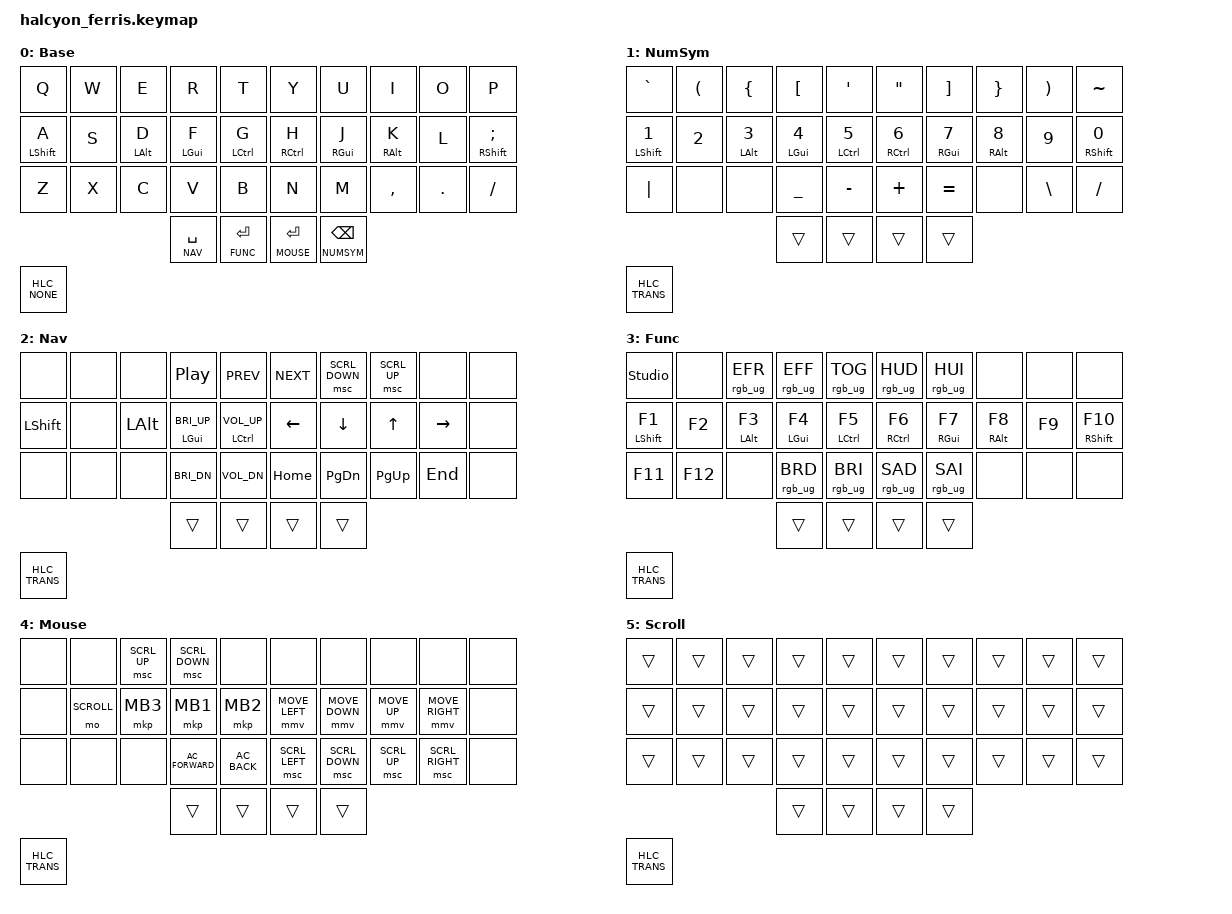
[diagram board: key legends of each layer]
/*
 * Halcyon Ferris keymap — 1:1 port of my ZSA Voyager Oryx layout
 * "Nima's 34 keys" (layout eVJKy, revision pjMjbv).
 *
 * Only the 34 Voyager keys that were actually bound are used, so the
 * layout maps directly onto the Ferris. Layer numbers match Oryx.
 *
 * Hardware: Halcyon wireless controllers, coin cell battery boards,
 * e-paper display module on the left half, Cirque touchpad on the right half.
 * The touchpad works on every layer as a mouse automatically.
 * The wired copy (flake output `firmware-wired`, RP2040 controllers, same
 * modules, no dongle) builds from this same file: ZMK picks it by shield
 * name, so the two keyboards cannot drift apart.
 * (&studio_unlock works on whichever part is the central: the dongle on
 * the wireless build, the left half on the wired one.)
 *
 * Position reference (34 keys + 10 Halcyon module slots at the end):
 *
 *   0  1  2  3  4     5  6  7  8  9
 *  10 11 12 13 14    15 16 17 18 19
 *  20 21 22 23 24    25 26 27 28 29
 *           30 31    32 33
 */

// Wheel scrolling with the &msc keys (Nav and Mouse layers): units per
// tick at full speed, ZMK's default is 10. Raise/lower to taste.
#define ZMK_POINTING_DEFAULT_SCRL_VAL 400

#include <behaviors.dtsi>
#include <dt-bindings/zmk/bt.h>
#include <dt-bindings/zmk/keys.h>
#include <dt-bindings/zmk/pointing.h>
#include <dt-bindings/zmk/rgb.h>

#define BASE   0
#define NUMSYM 1
#define NAV    2
#define FUNC   3
#define MOUSE  4
#define SCROLL 5   // held via S on the Mouse layer: the touchpad scrolls

// Halcyon module key slots (unused by the e-paper / Cirque modules)
#define HLC_NONE  &none  &none  &none  &none  &none   &none  &none  &none  &none  &none
#define HLC_TRANS &trans &trans &trans &trans &trans  &trans &trans &trans &trans &trans

// Key position groups for positional hold-taps (module slots 34-43 excluded).
#define KEYS_L 0 1 2 3 4  10 11 12 13 14  20 21 22 23 24
#define KEYS_R 5 6 7 8 9  15 16 17 18 19  25 26 27 28 29
#define THUMBS 30 31 32 33

// Layer-taps (thumbs): "balanced" = the layer wins as soon as a key on it is
// pressed *and released* while the thumb is down, so "hold Space, tap J"
// gives Down immediately instead of " j" during the first 200 ms.
// Thumbs don't roll with letters, so this doesn't cause misfires.
// Tap-then-hold within quick-tap-ms still auto-repeats Space / Backspace.
// The Mouse thumb uses &ltl (same timing, defined below) instead of &lt.
&lt {
    flavor = "balanced";
    tapping-term-ms = <200>;
    quick-tap-ms = <175>;
};

// &mt is now only used on the Nav layer (GUI / Ctrl on F / G, tapped for
// brightness / volume). hold-preferred: pressing any key while it is held
// applies the modifier right away (no rolling concerns on that layer).
&mt {
    flavor = "hold-preferred";
    tapping-term-ms = <200>;
    quick-tap-ms = <175>;
};

// Wheel scrolling keys reach full speed after this long (ZMK default 300 ms).
&msc {
    time-to-max-speed-ms = <150>;
};

/ {
    // "Timeless" home-row mods (the configuration recommended in the ZMK
    // hold-tap docs), replacing the QMK-style tap-preferred &mt:
    //  - balanced: a key pressed and released while the HRM is held -> hold,
    //    so Ctrl+C (hold H, tap C) works without first waiting 200 ms.
    //  - require-prior-idle-ms: when typing at speed (a key was pressed less
    //    than 100 ms ago) the HRM is a plain tap, no delay, no misfire.
    //  - hold-trigger-key-positions: a left-hand HRM only becomes a modifier
    //    when combined with a right-hand key or a thumb (and vice versa), so
    //    same-hand rolls like "as" / "df" / "jk" never produce mods. Holding
    //    past tapping-term-ms still gives the mod for deliberate same-hand use.
    //  - hold-trigger-on-release: lets you stack mods on one hand (Ctrl+Shift).
    behaviors {
        // Mouse thumb. The touchpad's auto Mouse layer (&zip_temp_layer in
        // the dongle / wired-left overlays) also targets layer 4 and, since
        // layer state is a plain bitmask, cannot tell that the thumb is
        // holding it: the first pad movement makes it adopt the layer and
        // its timeout then switches it off under the thumb (600 ms after the
        // last movement, so e.g. after a pad scroll the S release landed on
        // Base, and a paused drag typed letters). &mol holds the layer
        // *locked*: ZMK ignores a non-locking deactivate (the processor's
        // timeout and its "other key ends it" rule) on a locked layer, and
        // the thumb's own release clears the lock again. The processor sees
        // that release as a layer change and resets itself, so nothing
        // sticks; the auto layer still works on its own as before.
        mol: momentary_layer_locking {
            compatible = "zmk,behavior-momentary-layer";
            #binding-cells = <1>;
            locking;
        };

        ltl: layer_tap_locking {
            compatible = "zmk,behavior-hold-tap";
            #binding-cells = <2>;
            flavor = "balanced";
            tapping-term-ms = <200>;
            quick-tap-ms = <175>;
            bindings = <&mol>, <&kp>;
        };

        hml: home_row_mod_left {
            compatible = "zmk,behavior-hold-tap";
            #binding-cells = <2>;
            flavor = "balanced";
            require-prior-idle-ms = <100>;
            tapping-term-ms = <280>;
            quick-tap-ms = <175>;
            bindings = <&kp>, <&kp>;
            hold-trigger-key-positions = <KEYS_R THUMBS>;
            hold-trigger-on-release;
        };

        hmr: home_row_mod_right {
            compatible = "zmk,behavior-hold-tap";
            #binding-cells = <2>;
            flavor = "balanced";
            require-prior-idle-ms = <100>;
            tapping-term-ms = <280>;
            quick-tap-ms = <175>;
            bindings = <&kp>, <&kp>;
            hold-trigger-key-positions = <KEYS_L THUMBS>;
            hold-trigger-on-release;
        };
    };

    // Combos from the Oryx layout (active on all layers, 50 ms term
    // like QMK's default COMBO_TERM).
    // E+R and O+P sit on very common English bigrams ("there", "open"), so
    // they only fire after a short typing pause (require-prior-idle-ms);
    // this also removes the 50 ms combo wait on E/R/O/P while typing fast.
    combos {
        compatible = "zmk,combos";

        combo_esc {          // E + R
            key-positions = <2 3>;
            bindings = <&kp ESC>;
            timeout-ms = <50>;
            require-prior-idle-ms = <100>;
        };

        combo_del {          // O + P
            key-positions = <8 9>;
            bindings = <&kp DEL>;
            timeout-ms = <50>;
            require-prior-idle-ms = <100>;
        };

        combo_tab {          // C + V
            key-positions = <22 23>;
            bindings = <&kp TAB>;
            timeout-ms = <50>;
        };

        combo_tmux_prefix {  // J + K -> Ctrl+B (Oryx macro "tmuxprefix")
            key-positions = <16 17>;
            bindings = <&kp LC(B)>;
            timeout-ms = <50>;
        };
    };

    keymap {
        compatible = "zmk,keymap";

        base_layer {
            display-name = "Base";
// -----------------------------------------------------------------------------
// |   Q    |   W   |   E    |   F    |   T    |   |   Y    |   U    |   I    |   O   |   P    |
// | SHFT/A |   S   | ALT/D  | GUI/F  | CTL/G  |   | CTL/H  | GUI/J  | ALT/K  |   L   | SHFT/; |
// |   Z    |   X   |   C    |   V    |   B    |   |   N    |   M    |   ,    |   .   |   /    |
//                        | NAV/SPC | FUNC/ENT |   | MOUSE/ENT | NUMSYM/BSPC |
            bindings = <
&kp Q         &kp W  &kp E        &kp R        &kp T           &kp Y         &kp U        &kp I        &kp O   &kp P
&hml LSHFT A  &kp S  &hml LALT D  &hml LGUI F  &hml LCTRL G    &hmr RCTRL H  &hmr RGUI J  &hmr RALT K  &kp L   &hmr RSHFT SEMI
&kp Z         &kp X  &kp C        &kp V        &kp B           &kp N         &kp M        &kp COMMA    &kp DOT &kp FSLH
                            &lt NAV SPACE  &lt FUNC ENTER  &ltl MOUSE ENTER  &lt NUMSYM BSPC
HLC_NONE
            >;
        };

        numsym_layer {
            display-name = "NumSym";
// -----------------------------------------------------------------------------
// |   `    |   (   |   {    |   [    |   '    |   |   "    |   ]    |   }    |   )   |   ~    |
// | SHFT/1 |   2   | ALT/3  | GUI/4  | CTL/5  |   | CTL/6  | GUI/7  | ALT/8  |   9   | SHFT/0 |
// |   |    |       |        |   _    |   -    |   |   +    |   =    |        |   \   |   /    |
//                           |        |        |   |        |        |
            bindings = <
&kp GRAVE      &kp LPAR  &kp LBRC      &kp LBKT      &kp SQT          &kp DQT        &kp RBKT      &kp RBRC      &kp RPAR  &kp TILDE
&hml LSHFT N1  &kp N2    &hml LALT N3  &hml LGUI N4  &hml LCTRL N5    &hmr RCTRL N6  &hmr RGUI N7  &hmr RALT N8  &kp N9    &hmr RSHFT N0
&kp PIPE      &none     &none         &kp UNDER     &kp MINUS        &kp PLUS      &kp EQUAL    &none        &kp BSLH  &kp FSLH
                                      &trans        &trans           &trans        &trans
HLC_TRANS
            >;
        };

        nav_layer {
            display-name = "Nav";
// -----------------------------------------------------------------------------
// |        |       |        |  PLAY  |  PREV  |   |  NEXT  | SCR DN | SCR UP |       |        |
// |  SHFT  |       |  ALT   |GUI/BRI+|CTL/VOL+|   |  LEFT  |  DOWN  |   UP   | RIGHT |        |
// |        |       |        |  BRI-  |  VOL-  |   |  HOME  |  PGDN  |  PGUP  |  END  |        |
//                           |        |        |   |        |        |
            bindings = <
&none      &none  &none     &kp C_PP            &kp C_PREV            &kp C_NEXT  &msc SCRL_DOWN  &msc SCRL_UP  &none      &none
&kp LSHFT  &none  &kp LALT  &mt LGUI C_BRI_UP   &mt LCTRL C_VOL_UP    &kp LEFT    &kp DOWN        &kp UP        &kp RIGHT  &none
&none      &none  &none     &kp C_BRI_DN        &kp C_VOL_DN          &kp HOME    &kp PG_DN       &kp PG_UP     &kp END    &none
                                      &trans        &trans           &trans        &trans
HLC_TRANS
            >;
        };

        func_layer {
            display-name = "Func";
// -----------------------------------------------------------------------------
// | STUDIO |       |RGB EFR |RGB EFF | RGB TOG|   |RGB HUD |RGB HUI |        |       |        |
// | SHFT/F1|  F2   | ALT/F3 | GUI/F4 | CTL/F5 |   | CTL/F6 | GUI/F7 | ALT/F8 |  F9   |SHFT/F10|
// |  F11   |  F12  |        |  RGB-  |  RGB+  |   |RGB SAD |RGB SAI |        |       |        |
//                           |        |        |   |        |        |
// STUDIO = &studio_unlock (not in the Oryx layout; needed to edit via zmk.studio)
// RGB TOG = underglow on/off, RGB EFR/EFF = previous/next effect,
// RGB HUD/HUI = colour (hue) down/up, RGB SAD/SAI = saturation down/up
// (paler/stronger; replaces Oryx's second F11/F12, still on Z/X)
            bindings = <
&studio_unlock &none   &rgb_ug RGB_EFR &rgb_ug RGB_EFF &rgb_ug RGB_TOG   &rgb_ug RGB_HUD &rgb_ug RGB_HUI &none    &none   &none
&hml LSHFT F1  &kp F2  &hml LALT F3  &hml LGUI F4     &hml LCTRL F5      &hmr RCTRL F6  &hmr RGUI F7  &hmr RALT F8  &kp F9  &hmr RSHFT F10
&kp F11       &kp F12  &none        &rgb_ug RGB_BRD  &rgb_ug RGB_BRI    &rgb_ug RGB_SAD &rgb_ug RGB_SAI &none     &none   &none
                                      &trans        &trans           &trans        &trans
HLC_TRANS
            >;
        };

        mouse_layer {
            display-name = "Mouse";
// -----------------------------------------------------------------------------
// |        |       | SCR UP | SCR DN |        |   |        |        |        |       |        |
// |        | SCROLL|  MB3   |  MB1   |  MB2   |   | MS LT  | MS DN  | MS UP  | MS RT |        |
// |        |       |        |  FWD   |  BACK  |   | SCR LT | SCR DN | SCR UP | SCR RT|        |
// SCROLL = hold: the touchpad scrolls instead of moving the cursor
// BACK/FWD = browser back/forward (&kp C_AC_BACK / C_AC_FORWARD)
//                           |        |        |   |        |        |
            bindings = <
&none  &none  &msc SCRL_UP  &msc SCRL_DOWN  &none    &none           &none           &none         &none            &none
&none  &mo SCROLL  &mkp MB3  &mkp MB1    &mkp MB2     &mmv MOVE_LEFT  &mmv MOVE_DOWN  &mmv MOVE_UP  &mmv MOVE_RIGHT  &none
&none  &none  &none     &kp C_AC_FORWARD  &kp C_AC_BACK    &msc SCRL_LEFT  &msc SCRL_DOWN  &msc SCRL_UP  &msc SCRL_RIGHT  &none
                                      &trans        &trans           &trans        &trans
HLC_TRANS
            >;
        };

        scroll_layer {
            display-name = "Scroll";
// Held via S on the Mouse layer. Only exists so the dongle can tell "the
// touchpad should scroll" apart from the Mouse layer, which switches on by
// itself whenever the touchpad is used. Every key falls through.
            bindings = <
&trans &trans &trans &trans &trans    &trans &trans &trans &trans &trans
&trans &trans &trans &trans &trans    &trans &trans &trans &trans &trans
&trans &trans &trans &trans &trans    &trans &trans &trans &trans &trans
                                      &trans        &trans           &trans        &trans
HLC_TRANS
            >;
        };
    };
};
